VERSION ""

NS_ :

BS_:

BU_:

BO_ 2364575486 ImmoStateLockCode: 8 Vector__XXX
 SG_ ImmoStateLockCode : 1|31@1+ (1,0) [0|0] "" Vector__XXX

BO_ 2364571390 DriveSecurityStateLockCode: 8 Vector__XXX
 SG_ DriveSecurityStateLockCode : 1|31@1+ (1,0) [0|0] "" Vector__XXX

BO_ 2364575742 ImmoStateAck2: 8 Vector__XXX
 SG_ ImmoStateAck2 : 32|2@1+ (1,0) [0|3] "" Vector__XXX
 SG_ ImmoStateAck2LockCode : 1|31@1+ (1,0) [0|0] "" Vector__XXX

BO_ 2364571646 ImmoStateAck1: 8 Vector__XXX
 SG_ ImmoStateAck1LockCode : 1|31@1+ (1,0) [0|0] "" Vector__XXX
 SG_ ImmoStateAck1 : 32|2@1+ (1,0) [0|3] "" Vector__XXX

BO_ 2364567550 DriveSecurityStateAck: 8 Vector__XXX
 SG_ DriveSecurityStateAckLockCode : 1|31@1+ (1,0) [0|0] "" Vector__XXX
 SG_ DriveSecurityStateAck : 32|2@1+ (1,0) [0|3] "" Vector__XXX

BO_ 2364552702 ImmoState: 1 Vector__XXX
 SG_ ImmoState : 0|2@1+ (1,0) [0|3] "" Vector__XXX

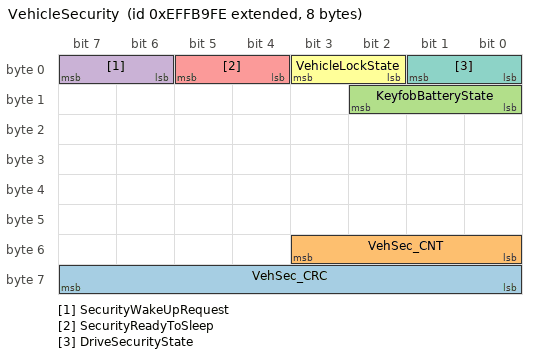
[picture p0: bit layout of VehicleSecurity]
BO_ 2399123966 VehicleSecurity: 8 Vector__XXX
 SG_ VehSec_CRC : 56|8@1+ (1,0) [0|255] "" Vector__XXX
 SG_ VehSec_CNT : 48|4@1+ (1,0) [0|15] "" Vector__XXX
 SG_ KeyfobBatteryState : 8|3@1+ (1,0) [0|7] "" Vector__XXX
 SG_ SecurityWakeUpRequest : 6|2@1+ (1,0) [0|3] "" Vector__XXX
 SG_ SecurityReadyToSleep : 4|2@1+ (1,0) [0|3] "" Vector__XXX
 SG_ VehicleLockState : 2|2@1+ (1,0) [0|3] "" Vector__XXX
 SG_ DriveSecurityState : 0|2@1+ (1,0) [0|3] "" Vector__XXX

CM_ "$File: //depot/auto/dbc/Components/Comunication_module/ArrivalSecurity/0.1.2.0/ArrivalSecurity.dbc $
$Change: 215963 $
$DateTime: 2024/08/21 09:46:28 $
$Revision: #1 $";
CM_ BO_ 2364571390 "For DEBUG-TEST only! Consist of signals that can replace AIN siganls from Analog button block";
CM_ BO_ 2399123966 "For DEBUG-TEST only! Consist of signals that can replace AIN siganls from Analog button block";
CM_ SG_ 2399123966 KeyfobBatteryState "Actual State of the Keyfob Battery";
BA_DEF_ SG_  "SigType" ENUM  "Default","Range","RangeSigned","ASCII","Discrete","Control","ReferencePGN","DTC","StringDelimiter","StringLength","StringLengthControl","MessageCounter","MessageChecksum";
BA_DEF_ SG_  "GenSigEVName" STRING ;
BA_DEF_ SG_  "GenSigILSupport" ENUM  "No","Yes";
BA_DEF_ SG_  "GenSigSendType" ENUM  "Cyclic","OnWrite","OnWriteWithRepetition","OnChange","OnChangeWithRepetition","IfActive","IfActiveWithRepetition","NoSigSendType";
BA_DEF_ BO_  "SendOnChange" ENUM  "No","Yes";
BA_DEF_ SG_  "GenSigStartValue" INT 0 2147483647;
BA_DEF_ BO_  "GenMsgDelayTime" INT 0 1000;
BA_DEF_ BO_  "GenMsgILSupport" ENUM  "No","Yes";
BA_DEF_ BU_  "NmStationAddress" INT 0 255;
BA_DEF_ BO_  "GenMsgSendType" ENUM  "cyclic","NotUsed","IfActive","NotUsed","NotUsed","NotUsed","NotUsed","NotUsed","noMsgSendType";
BA_DEF_ BO_  "GenMsgRequestable" INT 0 1;
BA_DEF_ BO_  "GenMsgCycleTime" INT 0 3600000;
BA_DEF_ SG_  "SPN" INT 0 524287;
BA_DEF_  "DBName" STRING ;
BA_DEF_  "BusType" STRING ;
BA_DEF_  "ProtocolType" STRING ;
BA_DEF_ BO_  "VFrameFormat" ENUM  "StandardCAN","ExtendedCAN","reserved","J1939PG";
BA_DEF_ BO_  "Producer" STRING ;
BA_DEF_DEF_  "SigType" "Default";
BA_DEF_DEF_  "GenSigEVName" "Env@Nodename_@Signame";
BA_DEF_DEF_  "GenSigILSupport" "Yes";
BA_DEF_DEF_  "GenSigSendType" "NoSigSendType";
BA_DEF_DEF_  "SendOnChange" "No";
BA_DEF_DEF_  "GenSigStartValue" 0;
BA_DEF_DEF_  "GenMsgDelayTime" 0;
BA_DEF_DEF_  "GenMsgILSupport" "Yes";
BA_DEF_DEF_  "NmStationAddress" 254;
BA_DEF_DEF_  "GenMsgSendType" "noMsgSendType";
BA_DEF_DEF_  "GenMsgRequestable" 1;
BA_DEF_DEF_  "GenMsgCycleTime" 0;
BA_DEF_DEF_  "SPN" 0;
BA_DEF_DEF_  "DBName" "";
BA_DEF_DEF_  "BusType" "CAN";
BA_DEF_DEF_  "ProtocolType" "J1939";
BA_DEF_DEF_  "VFrameFormat" "J1939PG";
BA_ "DBName" "Security";
BA_ "GenMsgSendType" BO_ 2364575486 0;
BA_ "GenMsgCycleTime" BO_ 2364575486 100;
BA_ "GenMsgSendType" BO_ 2364571390 0;
BA_ "GenMsgCycleTime" BO_ 2364571390 100;
BA_ "GenMsgCycleTime" BO_ 2364575742 100;
BA_ "GenMsgSendType" BO_ 2364575742 0;
BA_ "GenMsgSendType" BO_ 2364571646 0;
BA_ "GenMsgCycleTime" BO_ 2364571646 100;
BA_ "GenMsgSendType" BO_ 2364567550 0;
BA_ "GenMsgCycleTime" BO_ 2364567550 100;
BA_ "SendOnChange" BO_ 2364552702 1;
BA_ "GenMsgSendType" BO_ 2364552702 0;
BA_ "GenMsgCycleTime" BO_ 2364552702 1000;
BA_ "GenMsgDelayTime" BO_ 2364552702 100;
BA_ "GenMsgCycleTime" BO_ 2399123966 100;
BA_ "GenMsgSendType" BO_ 2399123966 0;
BA_ "SigType" SG_ 2399123966 VehSec_CRC 12;
BA_ "SigType" SG_ 2399123966 VehSec_CNT 11;
BA_ "SPN" SG_ 2399123966 KeyfobBatteryState 520006;
BA_ "SPN" SG_ 2399123966 SecurityWakeUpRequest 520005;
BA_ "GenSigStartValue" SG_ 2399123966 SecurityWakeUpRequest 3;
BA_ "SPN" SG_ 2399123966 SecurityReadyToSleep 520004;
BA_ "GenSigStartValue" SG_ 2399123966 SecurityReadyToSleep 3;
BA_ "SPN" SG_ 2399123966 VehicleLockState 520003;
BA_ "SPN" SG_ 2399123966 DriveSecurityState 520002;
BA_ "Producer" BO_ 2364552702 "SECSYS";
BA_ "Producer" BO_ 2364567550 "SECSYS";
BA_ "Producer" BO_ 2364575486 "SECSYS";
VAL_ 2364575742 ImmoStateAck2 3 "NA" 2 "Error" 1 "ACK" 0 "NACK" ;
VAL_ 2364571646 ImmoStateAck1 3 "NA" 2 "Error" 1 "ACK" 0 "NACK" ;
VAL_ 2364567550 DriveSecurityStateAck 3 "NA" 2 "Error" 1 "ACK" 0 "NACK" ;
VAL_ 2364552702 ImmoState 3 "NA" 2 "Error" 1 "Unlocked" 0 "Locked" ;
VAL_ 2399123966 KeyfobBatteryState 7 "NA" 6 "Error" 5 "Reserved" 4 "Reserved" 3 "Reserved" 2 "Critical Level" 1 "Low Level" 0 "Battery OK" ;
VAL_ 2399123966 SecurityWakeUpRequest 3 "NA" 2 "Error" 1 "SecurityWakeUp" 0 "SecurityNotWakeUp" ;
VAL_ 2399123966 SecurityReadyToSleep 3 "NA" 2 "Error" 1 "Security Ready" 0 "Security Not Ready" ;
VAL_ 2399123966 VehicleLockState 3 "NA" 2 "Error" 1 "Unlocked" 0 "Locked" ;
VAL_ 2399123966 DriveSecurityState 3 "NA" 2 "Error" 1 "Unlocked" 0 "Locked" ;
